# RN821X_RN721X_SOC_V3 register map
File version: v1.0.4
Renergy Metering RN821X RN721X SOC
CPU: CM0 r0p0, little endian, no MPU, no FPU, 3 interrupt priority bits
Registers are 32-bit, read-write, reset 0x0 unless marked. A register's access mark holds for its fields unless they carry their own. Offsets are from the block's base; lines under a group give offsets from that group; [hi:lo] are bit positions; {n}, {i} and the like mark numbered series; 'fields as' and 'values as' point back to an identical list; <NAME> marks a mode.

## Memory map
0x40000000 UART0 size 0x6C — UART tranceiver
0x40004000 UART1 size 0x6C
0x40008000 UART2 size 0x6C
0x4000C000 UART3 size 0x6C
0x40014000 TC1 size 0x50 — A 32-bit timer
0x40018000 UART4 size 0x6C
0x4001C000 UART5 size 0x6C
0x40024000 I2C size 0x14 — I2C controller
0x40028000 KBI size 0x10 — key detection
0x4002C000 MADC size 0x44 — analog peripherals
0x40030000 WDT size 0x20 — watchdog timer
0x40034000 SYSCTL size 0x11C — system control
0x4003C000 RTC size 0x18C — real time clock
0x40040000 NVM size 0x58 — no voltage module
0x40044000 INTC size 0x10 — interrupt controller for off-chip interrupt requests
0x40048000 LCD size 0x46 — liquid crystal display
0x40050000 SPI1 size 0x38 — synchronous peripheral interface
0x40058000 SPI3 size 0x38
0x40060000 SIMP_TC0 size 0xC — simple tc
0x4006000C SIMP_TC1 size 0xC
0x40060018 SIMP_TC2 size 0xC
0x40060024 SIMP_TC3 size 0xC
0x4006C000 IOCNT size 0x74 — emu pulse forwarding module
0x50000000 GPIO size 0x110
0x50004000 EMU size 0x4D0 — energy metering unit

## Interrupts
0 SYSCLKCAL (SYSCTL) — 16 SYSCLK CALC or EMU_RCD(v2/v3) Interrupt
3 RTC — 19 RTC Interrupt
4 EMU — 20 EMU or D2F(v2) Interrupt
5 MADC — 21 MADC or FLK(v2) Interrupt
6 UART0 — 22 UART0 Interrupt
7 UART1 — 23 UART1 Interrupt
8 UART2 — 24 UART2 Interrupt
9 UART3 — 25 UART3 Interrupt
11 I2C — 27 IIC Interrupt
15 TC1 — 31 Timer/Counter 1 Interrupt
16 UART4 — 32 UART4 Interrupt
17 UART5 — 33 UART5 Interrupt
18 WDT — 34 Watch Dog Interrupt
19 KBI — 35 Key Interrupt
20 LCD — 36 LCD and DSP(v2) Interrupt
23 NVM — 39 NVM or SPI1 Interrupt
24 EXT0 (INTC) — 40 Extern0 Interrupt (or all extern irq)
25 EXT1 (SIMP_TC0) — 41 Extern1 Interrupt (v2/v3 share with simp-tc0)
26 EXT2 (SIMP_TC1) — 42 Extern2 Interrupt (v2/v3 share with simp-tc1)
27 EXT3 (SIMP_TC2) — 43 Extern3 Interrupt (v2/v3 share with simp-tc2)
28 EXT4 (SIMP_TC3) — 44 Extern4 Interrupt (v2/v3 share with simp-tc3)

## I2C — I2C controller
Base 0x40024000
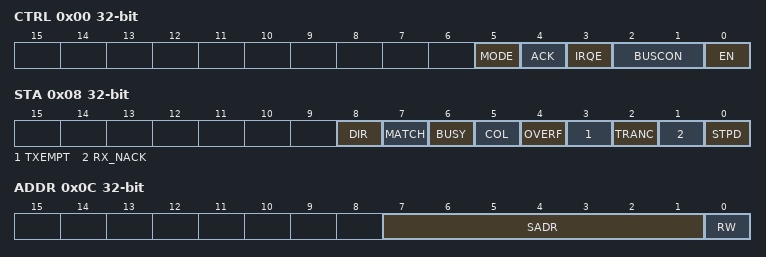
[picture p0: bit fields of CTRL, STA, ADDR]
0x00 CTRL — I2C control register
  [5] MODE — I2C slave/master mode selection bit
    0=S (select as slave device); 1=M (select as master device)
  [4] ACK — ACK signal configuration bit
    1=ACK (receive 9st SCL generate ACK); 0=NUL (receive 9st SCL donot generate ACK)
  [3] IRQE — I2C interrupt enable bit
  [2:1] BUSCON — I2C bus control bit (when finish command transmision clear automatically)
    0=NUL (no action); 1=START (generate start sequence (clear automatically when finish command transmision)); 2=STOP (generate stop sequence (clear automatically when finish command transmision))
  [0] EN — I2C module enable bit
0x04 CLK reset 0x1 — I2C clock configuration register
  [2:0] CLKDIV — I2C module clock divisor selection bits
    1=DEFAULT (select I2C module clock divisor as 10); 2=7M4_FM (when system clock = 7.3728Mhz, select I2C as fast speed mode, module clock set at system clock divided by 20); 3=14M7_FM (when system clock = 14.7456Mhz, select I2C as fast speed mode, module clock set at system clock divided by 38); 4=29M5_FM (when system clock = 29.4912Mhz, select I2C as fast speed mode, module clock set at system clock divided by 76); 2=1M8_SM (when system clock = 1.8432Mhz , select I2C as standard speed mode, module clock set at system clock divided by 20); 3=3M6_SM (when system clock = 3.6864Mhz , select I2C as standard speed mode, module clock set at system clock divided by 38); 4=7M4_SM (when system clock = 7.3728Mhz , select I2C as standard speed mode, module clock set at system clock divided by 76); 5=14M7_SM (when system clock = 14.7456Mhz, select I2C as standard speed mode, module clock set at system clock divided by 154); 6=29M5_SM (when system clock = 29.4912Mhz, select I2C as standard speed mode, module clock set at system clock divided by 306)
0x08 STA — I2C status indicate register
  [8] DIR ro — receive/transmit direction flag
    0=T (device as transmitting status); 1=R (device as receiving status)
  [7] MATCH ro — address match flag
  [6] BUSY ro — communication busy flag
  [5] COL write-1-clears — interrupt flag of transmit conflict
  [4] OVERF write-1-clears — interrupt flag of receive data overflow
  [3] TXEMPT write-1-clears — transmit data registor empty error flag
  [2] TRANC write-1-clears — interrupt flag of transmit finish
  [1] RX_NACK write-1-clears — interrupt flag of receive NACK interrupt
  [0] STPD write-1-clears — interrupt flag of stop time sequence detection
0x0C ADDR — I2C slave device address register
  [7:1] SADR — device address configuration bits
  [0] RW — receive/transmit direction configuration bit
    0=T (configuration as transmit device); 1=R (configuration as receive device)
0x10 DATA — I2C data transmit/receive register
  [7:0] DATA — I2C transfer data bits
